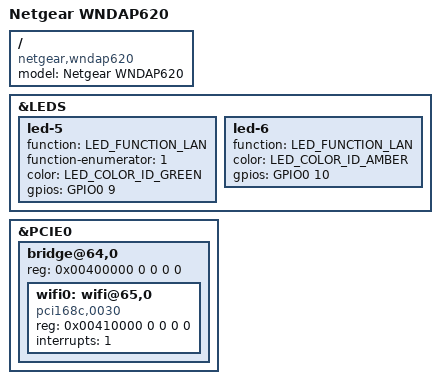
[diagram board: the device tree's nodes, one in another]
// SPDX-License-Identifier: GPL-2.0-only

/dts-v1/;

#include "netgear-wndap6x0.dtsi"

/ {
	model = "Netgear WNDAP620";
	compatible = "netgear,wndap620", "apm,bluestone";
};

&LEDS {
	led-5 {
		function = LED_FUNCTION_LAN;
		function-enumerator = <1>;
		color = <LED_COLOR_ID_GREEN>;
		gpios = <&GPIO0 9 GPIO_ACTIVE_HIGH>;
	};

	led-6 {
		function = LED_FUNCTION_LAN;
		color = <LED_COLOR_ID_AMBER>;
		gpios = <&GPIO0 10 GPIO_ACTIVE_HIGH>;
	};
};

&PCIE0 {
	/*
	 * relevant lspci topology:
	 *
	 *	-+-[0000:40]---00.0-[41-7f]----00.0
	 */

	bridge@64,0 {
		reg = <0x00400000 0 0 0 0>;
		#address-cells = <3>;
		#size-cells = <2>;
		ranges;

		wifi0: wifi@65,0 {
			/* Atheros AR9380 5GHz */
			compatible = "pci168c,0030";
			reg = <0x00410000 0 0 0 0>;
			interrupts = <1>; /* INTA */
		};
	};
};
